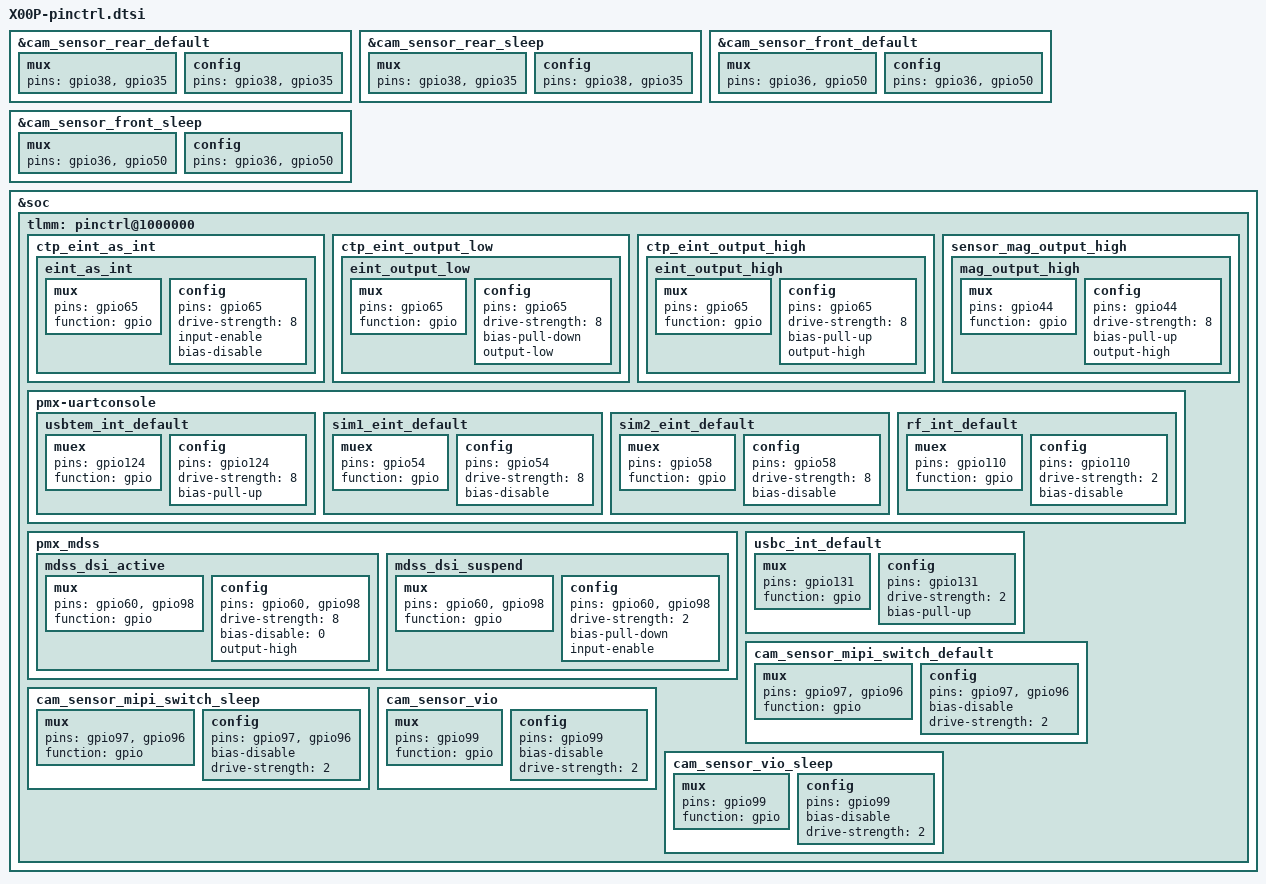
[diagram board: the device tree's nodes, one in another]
/*
 * Copyright (c) 2015-2017, The Linux Foundation. All rights reserved.
 *
 * This program is free software; you can redistribute it and/or modify
 * it under the terms of the GNU General Public License version 2 and
 * only version 2 as published by the Free Software Foundation.
 *
 * This program is distributed in the hope that it will be useful,
 * but WITHOUT ANY WARRANTY; without even the implied warranty of
 * MERCHANTABILITY or FITNESS FOR A PARTICULAR PURPOSE.  See the
 * GNU General Public License for more details.
 */

/* msm8937-pinctrl */

&cam_sensor_rear_default {
        mux {
                pins = "gpio38", "gpio35";
        };

        config {
                pins = "gpio38","gpio35";
        };
};

&cam_sensor_rear_sleep {
        mux {
                pins = "gpio38","gpio35";
        };

        config {
                pins = "gpio38","gpio35";
        };
};

&cam_sensor_front_default {
        mux {
                pins = "gpio36","gpio50";
        };

        config {
                pins = "gpio36","gpio50";
        };
};

&cam_sensor_front_sleep {
        mux {
                pins = "gpio36","gpio50";
        };

        config {
                pins = "gpio36","gpio50";
        };
};

&soc {
	tlmm: pinctrl@1000000 {

	  ctp_eint_as_int {
		eint_as_int: eint_as_int {
			mux {
				pins = "gpio65";
				function = "gpio";
			};
			config {
				pins = "gpio65";
				drive-strength = <8>;
				input-enable; 
				bias-disable;
			};
		};
	};
		
	ctp_eint_output_low {
		eint_output_low: eint_output_low {
			mux {
				pins = "gpio65";
				function = "gpio";
			};
			config {
				pins = "gpio65";
				drive-strength = <8>;
				bias-pull-down;
				output-low;
			};
		};
	};
	
	ctp_eint_output_high {
		eint_output_high: eint_output_high {
			mux {
				pins = "gpio65";
				function = "gpio";
			};
			config {
				pins = "gpio65";
				drive-strength = <8>;
				bias-pull-up;
				output-high;
			};
		};
	};
	
	sensor_mag_output_high {
		mag_output_high: mag_output_high {
			mux {
				pins = "gpio44";
				function = "gpio";
			};
			config {
				pins = "gpio44";
				drive-strength = <8>;
				bias-pull-up;
				output-high;
			};
		};
	};


	pmx-uartconsole {
		usbtem_int_default: usbtem_int_default {
			muex {
				pins = "gpio124";
				function = "gpio";
			};
			config {
				pins = "gpio124";
				drive-strength = <8>;
				bias-pull-up;
			};
		};

		sim1_eint_default: sim1_eint_default {
			muex {
				pins = "gpio54";
				function = "gpio";
			};
			config {
				pins = "gpio54";
				drive-strength = <8>;
				bias-disable;
			};
		};

		sim2_eint_default: sim2_eint_default {
			muex {
				pins = "gpio58";
				function = "gpio";
			};
			config {
				pins = "gpio58";
				drive-strength = <8>;
				bias-disable;
			};
		};
 
		rf_int_default: rf_int_default {
			muex {
				pins = "gpio110";
				function = "gpio";
			};
			config {
				pins = "gpio110";
				drive-strength = <2>;
				bias-disable;
				
			};
		};
	};

	pmx_mdss: pmx_mdss {
		mdss_dsi_active: mdss_dsi_active {
			mux {
				pins = "gpio60", "gpio98";
				function = "gpio";
			};
			config {
				pins = "gpio60", "gpio98";
				drive-strength = <8>; /* 8 mA */
				bias-disable = <0>; /* no pull */
				output-high;
			};
		};
		mdss_dsi_suspend: mdss_dsi_suspend {
			mux {
				pins = "gpio60", "gpio98";
				function = "gpio";
			};
			config {
				pins = "gpio60", "gpio98";
				drive-strength = <2>; /* 2 mA */
				bias-pull-down; /* pull down */
				input-enable;
			};
		};
	};

		usbc_int_default: usbc_int_default {
			mux {
				pins = "gpio131";
				function = "gpio";
			};

			config {
				pins = "gpio131";
				drive-strength = <2>;
				bias-pull-up;
			};
		};
 
        cam_sensor_mipi_switch_default: cam_sensor_mipi_switch_default {
			mux {
				pins = "gpio97", "gpio96";
				function = "gpio";
			};

			config {
				pins = "gpio97","gpio96";
				bias-disable; /* No PULL */
				drive-strength = <2>; /* 2 MA */
			};
		};

	cam_sensor_mipi_switch_sleep: cam_sensor_mipi_switch_sleep {
			mux {
				pins = "gpio97","gpio96";
				function = "gpio";
			};

			config {
				pins = "gpio97","gpio96";
				bias-disable; /* No PULL */
				drive-strength = <2>; /* 2 MA */
			};
		};
		
	cam_sensor_vio: cam_sensor_vio {
			mux {
				pins = "gpio99";
				function = "gpio";
			};

			config {
				pins = "gpio99";
				bias-disable; /* No PULL */
				drive-strength = <2>; /* 2 MA */
			};
		};

	cam_sensor_vio_sleep: cam_sensor_vio_sleep {
			mux {
				pins = "gpio99";
				function = "gpio";
			};

			config {
				pins = "gpio99";
				bias-disable; /* No PULL */
				drive-strength = <2>; /* 2 MA */
			};
		};
	};
};
